# ECM3532 register map
Vendor: EtaCompute; Series: ECM35xx; File version: 1.0.0
CPU: CM3 r1p1, little endian, MPU, no FPU, 3 interrupt priority bits
Registers are 32-bit, read-write, reset 0x0 unless marked. A register's access mark holds for its fields unless they carry their own. Offsets are from the block's base; [hi:lo] are bit positions; 'fields as' and 'values as' point back to an identical list.

## TIMER — The TIMER Device provides programmable timing support for an RTOS or RTOS surrogate, i.e. embedded firmware designs that don't use an RTOS. NOTE Some portions of the timer are only cleared by the initial power on reset to the SOC.
Base 0x50020400
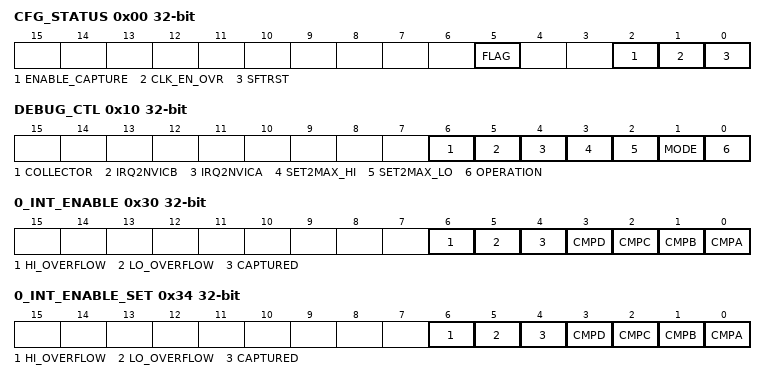
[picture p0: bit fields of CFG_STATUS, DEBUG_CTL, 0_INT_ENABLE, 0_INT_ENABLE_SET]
0x00 CFG_STATUS — Configuration and status bits for the TIMER.
  [5] FLAG ro — This bit toggles every time the counter is incremented. It is useful for ensuring a clean read of the full 64-bits of the counter. Note this bit is also visible in the GPIO external status register for faster read access.
  [2] ENABLE_CAPTURE — When this bit is set to 1 it enables the capture registers to respond to a pin transition event in the selected GPIO pin. This would also set the CAPTURE interrupt status bit when it occurs.
    1=ENABLE (Enable GPIO Event Capture.); 0=DISABLE (Disable GPIO Event Capture.)
  [1] CLK_EN_OVR — Force the clock enable for this module ON to prevent clock gating at the HFO. Intended for debug purposes.
    1=ENABLE (Prevent HFO clock gating.); 0=DISABLE (Allow HFO clock gating when block is inactive.)
  [0] SFTRST wo — Set this bit to one to perform a soft reset on the timer.
    1=NOW (Perform a soft reset.)
0x08 COUNTER_LO — Lower 32-bits of counter.
  [31:0] VALUE ro — This read only bit field provides a view of the lower 32 bits of the counter.
0x0C COUNTER_HI — Upper 32-bits of counter.
  [31:0] VALUE ro — This read only bit field provides a view of the upper 32 bits of the counter.
0x10 DEBUG_CTL — Various debug state control bits.
  [6] COLLECTOR ro — This read only bit fields collects a number of signals inside the timer block. This is an internal debug signal.
  [5] IRQ2NVICB ro — Provides a read only view of what the TIMER device is sending to the NVIC on either interrupt 1.
  [4] IRQ2NVICA ro — Provides a read only view of what the TIMER device is sending to the NVIC on either interrupt 0.
  [3] SET2MAX_HI wo — Writing a one to this bit will cause the high counter register to be set to its maximum count (0xFFFFFFFF). This is a diagnostic tool to check the effect of the counter rolling over from 0xFFFFFFFF to 0x00000000.
  [2] SET2MAX_LO wo — Writing a one to this bit will cause the counter register to be set to 4 before its maximum count (0xFFFFFFFC). This is a diagnostic tool to check the effect of the counter rolling over from 0xFFFFFFFF to 0x00000000.
  [1] MODE — Set to 1 to enable counting in the timer COUNT registers. Set to zero to stop the main counter and clear it. WARNING: setting this bit to 0 will cause the loss any real time epoch maintained in the timer counter register.
    1=ENABLE (Enable Normal Timer Operation.); 0=DISABLE (Disable Normal Timer Operation and clear the counter.)
  [0] OPERATION — Set to 0 to temporarily stop counting in the timer COUNT registers. WARNING: setting this bit to 0 will cause the loss any real time epoch maintained in the timer counter register. This state may be useful during firmware debug.
    1=RUN (Enable Normal Timer Operation.); 0=STOP (Disable Normal Timer Operation.)
0x14 DEBUG_READ_ONLY — Provide a read only value for diagnostics.
  [31:0] VALUE ro — Debug Read Only Value for Diagnostics.
0x18 CAPTURE_LO — Lower 32-bits of captured time of day.
  [31:0] VALUE — Read only view of lower 32-bits of the time of day that a GPIO event was detected.
0x1C CAPTURE_HI — Upper 32-bits of captured time of day.
  [31:0] VALUE — Read only view of upper 32-bits of the time of day that a GPIO event was detected.
0x20 COMPAREA — When this register value exactly matches the lower 32-bits of the counter then CMPA_STATUS interrupt status bit is set.
  [31:0] VALUE — When this register is loaded with a value and the CMPA_ENABLE bit is on, then it is armed to set an interrupt status bit when the counter value matches this value.
0x24 COMPAREB — When this register value exactly matches the lower 32-bits of the counter then CMPB_STATUS interrupt status bit is set.
  [31:0] VALUE — When this register is loaded with a value and the CMPB_ENABLE bit is on, then it is armed to set an interrupt status bit when the counter value matches this value.
0x28 COMPAREC — When this register value exactly matches the lower 32-bits of the counter then CMPC_STATUS interrupt status bit is set.
  [31:0] VALUE — When this register is loaded with a value and the CMPC_ENABLE bit is on, then it is armed to set an interrupt status bit when the counter value matches this value.
0x2C COMPARED — When this register value exactly matches the lower 32-bits of the counter then CMPD_STATUS interrupt status bit is set.
  [31:0] VALUE — When this register is loaded with a value and the CMPD_ENABLE bit is on, then it is armed to set an interrupt status bit when the counter value matches this value.
0x30 0_INT_ENABLE — Interrupt Enable register for the TIMER 0 interrupt.
  [6] HI_OVERFLOW — The upper 32-bits of the counter wrapped from 0xFFFFFFFF back to 0x00000000.
  [5] LO_OVERFLOW — The lower 32-bits of the counter wrapped from 0xFFFFFFFF back to 0x00000000.
  [4] CAPTURED — The selected GPIO pin made the designated transition. The capture registers contain the time of day at which this occurred.
  [3] CMPD — Comparator D matched the lower bits of the counter.
  [2] CMPC — Comparator C matched the lower bits of the counter.
  [1] CMPB — Comparator B matched the lower bits of the counter.
  [0] CMPA — Comparator A matched the lower bits of the counter.
0x34 0_INT_ENABLE_SET — Set Interrupt Enable bits for TIMER Interrupt 0
  [6] HI_OVERFLOW wo — Set the corresponding interrupt enable bit.
  [5] LO_OVERFLOW wo — Set the corresponding interrupt enable bit.
  [4] CAPTURED wo — Set the corresponding interrupt enable bit.
  [3] CMPD wo — Set the corresponding interrupt enable bit.
  [2] CMPC wo — Set the corresponding interrupt enable bit.
  [1] CMPB wo — Set the corresponding interrupt enable bit.
  [0] CMPA wo — Set the corresponding interrupt enable bit.
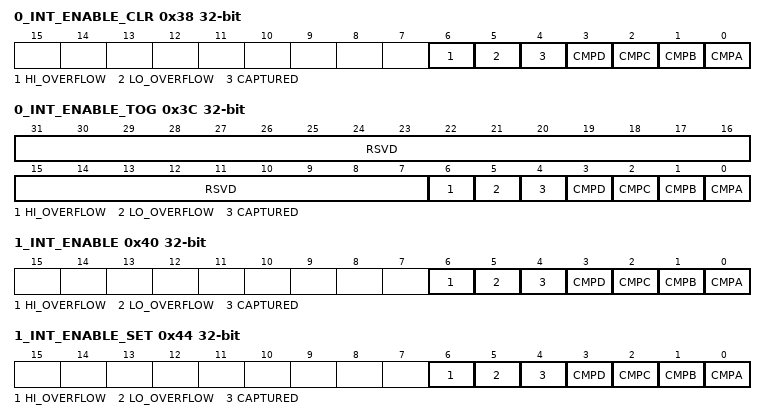
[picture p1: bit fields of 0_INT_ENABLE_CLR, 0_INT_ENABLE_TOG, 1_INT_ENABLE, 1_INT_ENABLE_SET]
0x38 0_INT_ENABLE_CLR — Set Interrupt Enable bits for TIMER Interrupt 0
  [6] HI_OVERFLOW wo — Clear the corresponding interrupt enable bit.
  [5] LO_OVERFLOW wo — Clear the corresponding interrupt enable bit.
  [4] CAPTURED wo — Clear the corresponding interrupt enable bit.
  [3] CMPD wo — Clear the corresponding interrupt enable bit.
  [2] CMPC wo — Clear the corresponding interrupt enable bit.
  [1] CMPB wo — Clear the corresponding interrupt enable bit.
  [0] CMPA wo — Clear the corresponding interrupt enable bit.
0x3C 0_INT_ENABLE_TOG — Toggle Interrupt Enable bits for TIMER Interrupt 0
  [31:7] RSVD ro — Toggle the corresponding interrupt enable bit.
  [6] HI_OVERFLOW wo — Toggle the corresponding interrupt enable bit.
  [5] LO_OVERFLOW wo — Toggle the corresponding interrupt enable bit.
  [4] CAPTURED wo — Toggle the corresponding interrupt enable bit.
  [3] CMPD wo — Toggle the corresponding interrupt enable bit.
  [2] CMPC wo — Toggle the corresponding interrupt enable bit.
  [1] CMPB wo — Toggle the corresponding interrupt enable bit.
  [0] CMPA wo — Toggle the corresponding interrupt enable bit.
0x40 1_INT_ENABLE — Interrupt Enable register for the TIMER interrupt 1.
  fields as 0_INT_ENABLE
0x44 1_INT_ENABLE_SET — Set Interrupt Enable bits for TIMER Interrupt 1
  fields as 0_INT_ENABLE_SET
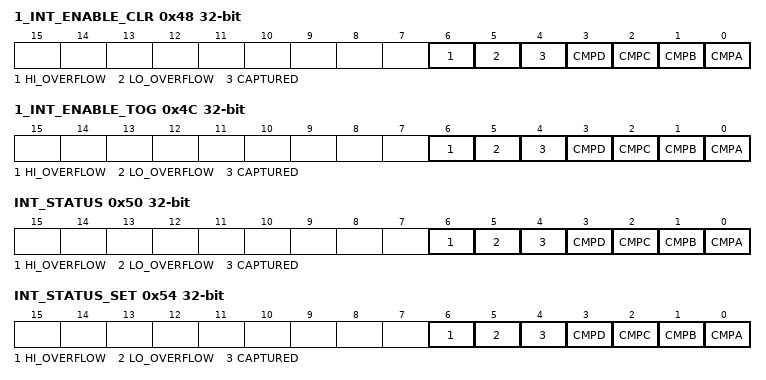
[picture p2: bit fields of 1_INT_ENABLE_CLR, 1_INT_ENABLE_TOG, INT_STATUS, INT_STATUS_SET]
0x48 1_INT_ENABLE_CLR — Set Interrupt Enable bits for TIMER Interrupt 1
  fields as 0_INT_ENABLE_CLR
0x4C 1_INT_ENABLE_TOG — Toggle Interrupt Enable bits for TIMER Interrupt 1
  fields as 0_INT_ENABLE
0x50 INT_STATUS — Interrupt Status register for the TIMER. Bits in this register can be routed to either timer_irq0 or timer_irq1 on their way to the NVIC.
  fields as 0_INT_ENABLE
0x54 INT_STATUS_SET — Set Interrupt Status bits for TIMER Interrupts.
  [6] HI_OVERFLOW wo — Set the interrupt status bit for the upper 32-bits of the counter wrapped from 0xFFFFFFFF back to 0x00000000.
  [5] LO_OVERFLOW wo — Set the interrupt status bit for the lower 32-bits of the counter wrapped from 0xFFFFFFFF back to 0x00000000.
  [4] CAPTURED wo — Set the interrupt status bit for the selected GPIO pin made the designated transition. The capture registers contain the time of day at which this occurred.
  [3] CMPD wo — Set the interrupt status bit for the Comparator D matched the lower bits of the counter.
  [2] CMPC wo — Set the interrupt status bit for the Comparator C matched the lower bits of the counter.
  [1] CMPB wo — Set the interrupt status bit for the Comparator B matched the lower bits of the counter.
  [0] CMPA wo — Set the interrupt status bit for the Comparator A matched the lower bits of the counter.
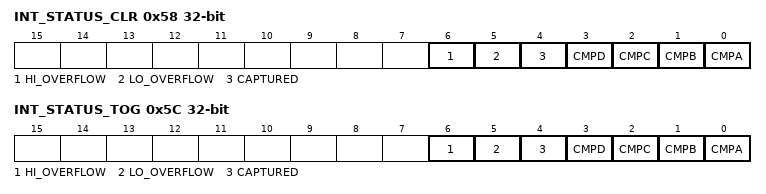
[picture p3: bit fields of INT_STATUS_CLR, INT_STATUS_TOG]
0x58 INT_STATUS_CLR — Clear Interrupt Status bits for TIMER Interrupts.
  [6] HI_OVERFLOW wo — Clear the interrupt status bit for the upper 32-bits of the counter wrapped from 0xFFFFFFFF back to 0x00000000.
  [5] LO_OVERFLOW wo — Clear the interrupt status bit for the lower 32-bits of the counter wrapped from 0xFFFFFFFF back to 0x00000000.
  [4] CAPTURED wo — Clear the interrupt status bit for the selected GPIO pin made the designated transition. The capture registers contain the time of day at which this occurred.
  [3] CMPD wo — Clear the interrupt status bit for the Comparator D matched the lower bits of the counter.
  [2] CMPC wo — Clear the interrupt status bit for the Comparator C matched the lower bits of the counter.
  [1] CMPB wo — Clear the interrupt status bit for the Comparator B matched the lower bits of the counter.
  [0] CMPA wo — Clear the interrupt status bit for the Comparator A matched the lower bits of the counter.
0x5C INT_STATUS_TOG — Toggle Interrupt Status bits for TIMER Interrupts.
  [6] HI_OVERFLOW wo — Toggle the interrupt status bit for the upper 32-bits of the counter wrapped from 0xFFFFFFFF back to 0x00000000.
  [5] LO_OVERFLOW wo — Toggle the interrupt status bit for the lower 32-bits of the counter wrapped from 0xFFFFFFFF back to 0x00000000.
  [4] CAPTURED wo — Toggle the interrupt status bit for the selected GPIO pin made the designated transition. The capture registers contain the time of day at which this occurred.
  [3] CMPD wo — Toggle the interrupt status bit for the Comparator D matched the lower bits of the counter.
  [2] CMPC wo — Toggle the interrupt status bit for the Comparator C matched the lower bits of the counter.
  [1] CMPB wo — Toggle the interrupt status bit for the Comparator B matched the lower bits of the counter.
  [0] CMPA wo — Toggle the interrupt status bit for the Comparator A matched the lower bits of the counter.
